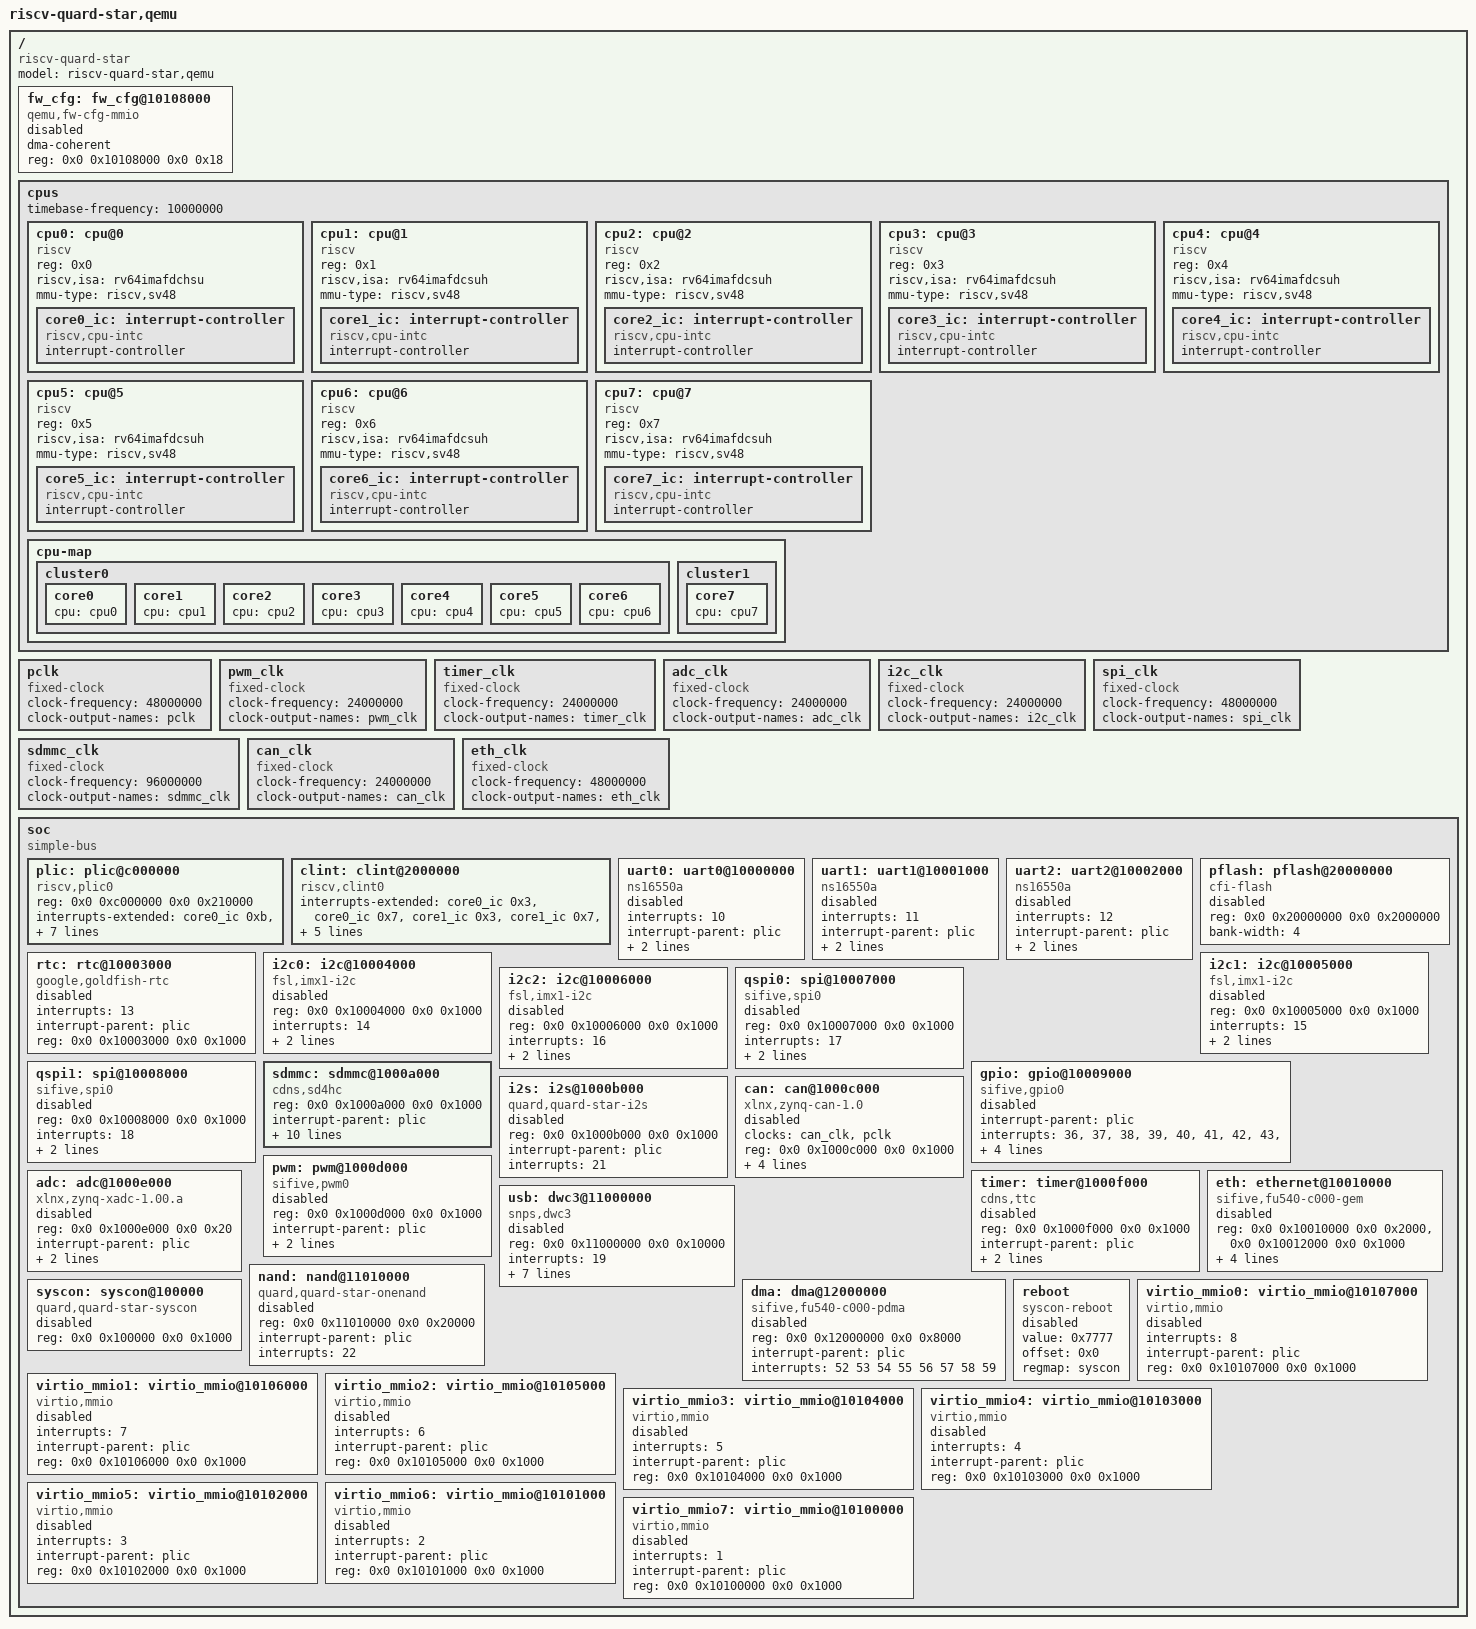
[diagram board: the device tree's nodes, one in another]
/dts-v1/;

/ {
	#address-cells = <0x2>;
	#size-cells = <0x2>;
	compatible = "riscv-quard-star";
	model = "riscv-quard-star,qemu";

	fw_cfg:fw_cfg@10108000 {
		dma-coherent;
		reg = <0x0 0x10108000 0x0 0x18>;
		compatible = "qemu,fw-cfg-mmio";
		status = "disabled";
	};

	cpus {
		#address-cells = <0x1>;
		#size-cells = <0x0>;
		timebase-frequency = <10000000>;

		cpu0: cpu@0 {
			device_type = "cpu";
			reg = <0x0>;
			status = "okay";
			compatible = "riscv";
			riscv,isa = "rv64imafdchsu";
			mmu-type = "riscv,sv48";

			core0_ic:interrupt-controller {
				#interrupt-cells = <0x1>;
				interrupt-controller;
				compatible = "riscv,cpu-intc";
			};
		};

		cpu1: cpu@1 {
			device_type = "cpu";
			reg = <0x1>;
			status = "okay";
			compatible = "riscv";
			riscv,isa = "rv64imafdcsuh";
			mmu-type = "riscv,sv48";

			core1_ic:interrupt-controller {
				#interrupt-cells = <0x1>;
				interrupt-controller;
				compatible = "riscv,cpu-intc";
			};
		};

		cpu2: cpu@2 {
			device_type = "cpu";
			reg = <0x2>;
			status = "okay";
			compatible = "riscv";
			riscv,isa = "rv64imafdcsuh";
			mmu-type = "riscv,sv48";

			core2_ic:interrupt-controller {
				#interrupt-cells = <0x1>;
				interrupt-controller;
				compatible = "riscv,cpu-intc";
			};
		};

		cpu3: cpu@3 {
			device_type = "cpu";
			reg = <0x3>;
			status = "okay";
			compatible = "riscv";
			riscv,isa = "rv64imafdcsuh";
			mmu-type = "riscv,sv48";

			core3_ic:interrupt-controller {
				#interrupt-cells = <0x1>;
				interrupt-controller;
				compatible = "riscv,cpu-intc";
			};
		};

		cpu4: cpu@4 {
			device_type = "cpu";
			reg = <0x4>;
			status = "okay";
			compatible = "riscv";
			riscv,isa = "rv64imafdcsuh";
			mmu-type = "riscv,sv48";

			core4_ic:interrupt-controller {
				#interrupt-cells = <0x1>;
				interrupt-controller;
				compatible = "riscv,cpu-intc";
			};
		};

		cpu5: cpu@5 {
			device_type = "cpu";
			reg = <0x5>;
			status = "okay";
			compatible = "riscv";
			riscv,isa = "rv64imafdcsuh";
			mmu-type = "riscv,sv48";

			core5_ic:interrupt-controller {
				#interrupt-cells = <0x1>;
				interrupt-controller;
				compatible = "riscv,cpu-intc";
			};
		};

		cpu6: cpu@6 {
			device_type = "cpu";
			reg = <0x6>;
			status = "okay";
			compatible = "riscv";
			riscv,isa = "rv64imafdcsuh";
			mmu-type = "riscv,sv48";

			core6_ic:interrupt-controller {
				#interrupt-cells = <0x1>;
				interrupt-controller;
				compatible = "riscv,cpu-intc";
			};
		};

		cpu7: cpu@7 {
			device_type = "cpu";
			reg = <0x7>;
			status = "okay";
			compatible = "riscv";
			riscv,isa = "rv64imafdcsuh";
			mmu-type = "riscv,sv48";

			core7_ic:interrupt-controller {
				#interrupt-cells = <0x1>;
				interrupt-controller;
				compatible = "riscv,cpu-intc";
			};
		};

		cpu-map {

			cluster0 {

				core0 {
					cpu = <&cpu0>;
				};

				core1 {
					cpu = <&cpu1>;
				};

				core2 {
					cpu = <&cpu2>;
				};

				core3 {
					cpu = <&cpu3>;
				};

				core4 {
					cpu = <&cpu4>;
				};

				core5 {
					cpu = <&cpu5>;
				};

				core6 {
					cpu = <&cpu6>;
				};
			};

			cluster1 {
				core7 {
					cpu = <&cpu7>;
				};
			};
		};
	};

	pclk:pclk {
		compatible="fixed-clock";
		clock-frequency=<48000000>;
		clock-output-names="pclk";
		#clock-cells = <0>;
	};

	pwm_clk:pwm_clk {
		compatible="fixed-clock";
		clock-frequency=<24000000>;
		clock-output-names="pwm_clk";
		#clock-cells = <0>;
	};

	timer_clk:timer_clk {
		compatible="fixed-clock";
		clock-frequency=<24000000>;
		clock-output-names="timer_clk";
		#clock-cells = <0>;
	};

	adc_clk:adc_clk {
		compatible="fixed-clock";
		clock-frequency=<24000000>;
		clock-output-names="adc_clk";
		#clock-cells = <0>;
	};

	i2c_clk:i2c_clk {
		compatible="fixed-clock";
		clock-frequency=<24000000>;
		clock-output-names="i2c_clk";
		#clock-cells = <0>;
	};
	
	spi_clk:spi_clk {
		compatible="fixed-clock";
		clock-frequency=<48000000>;
		clock-output-names="spi_clk";
		#clock-cells = <0>;
	};

	sdmmc_clk:sdmmc_clk {
		compatible="fixed-clock";
		clock-frequency=<96000000>;
		clock-output-names="sdmmc_clk";
		#clock-cells = <0>;
	};

	can_clk:can_clk {
		compatible="fixed-clock";
		clock-frequency=<24000000>;
		clock-output-names="can_clk";
		#clock-cells = <0>;
	};

	eth_clk:eth_clk {
		compatible="fixed-clock";
		clock-frequency=<48000000>;
		clock-output-names="eth_clk";
		#clock-cells = <0>;
	};

	soc {
		#address-cells = <0x2>;
		#size-cells = <0x2>;
		compatible = "simple-bus";
		ranges;

		plic:plic@c000000 {
			compatible = "riscv,plic0";
			reg = <0x0 0xc000000 0x0 0x210000>;
			#interrupt-cells = <0x1>;
			#address-cells = <0x0>;
			interrupts-extended = <&core0_ic 0xb &core0_ic 0x9>,
								  <&core1_ic 0xb &core1_ic 0x9>,
								  <&core2_ic 0xb &core2_ic 0x9>,
								  <&core3_ic 0xb &core3_ic 0x9>,
								  <&core4_ic 0xb &core4_ic 0x9>,
								  <&core5_ic 0xb &core5_ic 0x9>,
								  <&core6_ic 0xb &core6_ic 0x9>,
								  <&core7_ic 0xb &core7_ic 0x9>;
			interrupt-controller;
			riscv,ndev = <64>;
		};

		clint:clint@2000000 {
			interrupts-extended = <&core0_ic 0x3 &core0_ic 0x7>,
								  <&core1_ic 0x3 &core1_ic 0x7>,
								  <&core2_ic 0x3 &core2_ic 0x7>,
								  <&core3_ic 0x3 &core3_ic 0x7>,
								  <&core4_ic 0x3 &core4_ic 0x7>,
								  <&core5_ic 0x3 &core5_ic 0x7>,
								  <&core6_ic 0x3 &core6_ic 0x7>,
								  <&core7_ic 0x3 &core7_ic 0x7>;
			reg = <0x0 0x2000000 0x0 0x10000>;
			compatible = "riscv,clint0";
		};

		uart0:uart0@10000000 {
			interrupts = <10>;
			interrupt-parent = <&plic>;
			clock-frequency = <0x384000>;
			reg = <0x0 0x10000000 0x0 0x100>;
			compatible = "ns16550a";
			status = "disabled";
		};

		uart1:uart1@10001000 {
			interrupts = <11>;
			interrupt-parent = <&plic>;
			clock-frequency = <0x384000>;
			reg = <0x0 0x10001000 0x0 0x100>;
			compatible = "ns16550a";
			status = "disabled";
		};

		uart2:uart2@10002000 {
			interrupts = <12>;
			interrupt-parent = <&plic>;
			clock-frequency = <0x384000>;
			reg = <0x0 0x10002000 0x0 0x100>;
			compatible = "ns16550a";
			status = "disabled";
		};
		
		pflash:pflash@20000000 {
			compatible = "cfi-flash";
			reg = <0x0 0x20000000 0x0 0x2000000>;
			bank-width = <4>;
			status = "disabled";
		};
		
		rtc:rtc@10003000 {
			interrupts = <13>;
			interrupt-parent = <&plic>;
			reg = <0x0 0x10003000 0x0 0x1000>;
			compatible = "google,goldfish-rtc";
			status = "disabled";
		};

		i2c0: i2c@10004000 {
			#address-cells = <1>;
			#size-cells = <0>;
			compatible = "fsl,imx1-i2c";
			reg = <0x0 0x10004000 0x0 0x1000>;
			interrupts = <14>;
			interrupt-parent = <&plic>;
			clocks = <&i2c_clk>;
			status = "disabled";
		};
		
		i2c1: i2c@10005000 {
			#address-cells = <1>;
			#size-cells = <0>;
			compatible = "fsl,imx1-i2c";
			reg = <0x0 0x10005000 0x0 0x1000>;
			interrupts = <15>;
			interrupt-parent = <&plic>;
			clocks = <&i2c_clk>;
			status = "disabled";
		};		
		
		i2c2: i2c@10006000 {
			#address-cells = <1>;
			#size-cells = <0>;
			compatible = "fsl,imx1-i2c";
			reg = <0x0 0x10006000 0x0 0x1000>;
			interrupts = <16>;
			interrupt-parent = <&plic>;
			clocks = <&i2c_clk>;
			status = "disabled";
		};

		qspi0: spi@10007000 {
			#address-cells = <1>;
			#size-cells = <0>;
			compatible = "sifive,spi0";
			reg = <0x0 0x10007000 0x0 0x1000>;
			interrupts = <17>;
			interrupt-parent = <&plic>;
			clocks = <&spi_clk>;
			status = "disabled";
		};

		qspi1: spi@10008000 {
			#address-cells = <1>;
			#size-cells = <0>;
			compatible = "sifive,spi0";
			reg = <0x0 0x10008000 0x0 0x1000>;
			interrupts = <18>;
			interrupt-parent = <&plic>;
			clocks = <&spi_clk>;
			status = "disabled";
		};

		gpio: gpio@10009000 {
			compatible = "sifive,gpio0";
			interrupt-parent = <&plic>;
			interrupts = <36>, <37>, <38>, <39>, <40>, <41>, <42>, <43>,
						 <44>, <45>, <46>, <47>, <48>, <49>, <50>, <51>;
			reg = <0x0 0x10009000 0x0 0x1000>;
			gpio-controller;
			#gpio-cells = <2>;
			interrupt-controller;
			#interrupt-cells = <2>;
			status = "disabled";
		};

		sdmmc: sdmmc@1000a000 {
			compatible = "cdns,sd4hc";
			reg = <0x0 0x1000a000 0x0 0x1000>;
			interrupt-parent = <&plic>;
			interrupts = <20>;
			clocks = <&sdmmc_clk>;
			bus-width = <8>;
			mmc-ddr-1_8v;
			mmc-hs200-1_8v;
			cdns,phy-input-delay-legacy = <9>;
			cdns,phy-input-delay-mmc-highspeed = <2>;
			cdns,phy-input-delay-mmc-ddr = <3>;
			cdns,phy-dll-delay-sdclk = <21>;
			cdns,phy-dll-delay-sdclk-hsmmc = <21>;
		};

		i2s: i2s@1000b000 {
			compatible = "quard,quard-star-i2s";
			#sound-dai-cells = <0>;
			reg = <0x0 0x1000b000 0x0 0x1000>;
			interrupt-parent = <&plic>;
			interrupts = <21>;
			status = "disabled";
		};

		can: can@1000c000 {
			compatible = "xlnx,zynq-can-1.0";
			status = "disabled";
			clock-names = "can_clk", "pclk";
			clocks = <&can_clk>, <&pclk>;
			reg = <0x0 0x1000c000 0x0 0x1000>;
			interrupt-parent = <&plic>;
			interrupts = <23>;
			tx-fifo-depth = <0x40>;
			rx-fifo-depth = <0x40>;
		};

		pwm: pwm@1000d000 {
			compatible = "sifive,pwm0";
			reg = <0x0 0x1000d000 0x0 0x1000>;
			interrupt-parent = <&plic>;
			interrupts = <32>, <33>, <34>, <35>;
			clocks = <&pwm_clk>;
			#pwm-cells = <3>;
			status = "disabled";
		};

		adc: adc@1000e000 {
			compatible = "xlnx,zynq-xadc-1.00.a";
			reg = <0x0 0x1000e000 0x0 0x20>;
			interrupt-parent = <&plic>;
			interrupts = <24>;
			clocks = <&adc_clk>;
			status = "disabled";
		};

		timer: timer@1000f000 {
			compatible = "cdns,ttc";
			reg = <0x0 0x1000f000 0x0 0x1000>;
			interrupt-parent = <&plic>;
			interrupts = <29>, <30>, <31>;
			clocks = <&timer_clk>;
			status = "disabled";
		};

		eth: ethernet@10010000 {
			compatible = "sifive,fu540-c000-gem";
			reg = <0x0 0x10010000 0x0 0x2000>,
			      <0x0 0x10012000 0x0 0x1000>;
			interrupt-parent = <&plic>;
			interrupts = <25>;
			local-mac-address = [52 54 00 12 34 55];
			clock-names = "pclk", "hclk";
			clocks = <&eth_clk>, <&eth_clk>;
			#address-cells = <1>;
			#size-cells = <0>;
			status = "disabled";
		};

		usb: dwc3@11000000 {
			compatible = "snps,dwc3";
			reg = <0x0 0x11000000 0x0 0x10000>;
			interrupts = <19>;
			interrupt-parent = <&plic>;
			status = "disabled";
			phy-names = "usb3-phy";
			dr_mode = "host";
			snps,quirk-frame-length-adjustment = <0x20>;
			snps,dis_u2_susphy_quirk;
			snps,dis_u3_susphy_quirk;
			snps,refclk_fladj;
			snps,mask_phy_reset;
		};

		nand: nand@11010000 {
			compatible = "quard,quard-star-onenand";
			reg = <0x0 0x11010000 0x0 0x20000>;
			interrupt-parent = <&plic>;
			interrupts = <22>;
			status = "disabled";
		};

		dma: dma@12000000 {
			compatible = "sifive,fu540-c000-pdma";
			reg = <0x0 0x12000000 0x0 0x8000>;
			interrupt-parent = <&plic>;
			interrupts = <52 53 54 55 56 57 58 59>;
			#dma-cells = <1>;
			status = "disabled";
		};

		syscon:syscon@100000 {
			reg = <0x0 0x100000 0x0 0x1000>;
			compatible = "quard,quard-star-syscon","sifive,test1", "sifive,test0", "syscon";
			status = "disabled";
		};

		reboot:reboot {
			value = <0x7777>;
			offset = <0x0>;
			regmap = <&syscon>;
			compatible = "syscon-reboot";
			status = "disabled";
		};
	
		virtio_mmio0:virtio_mmio@10107000 {
			interrupts = <8>;
			interrupt-parent = <&plic>;
			reg = <0x0 0x10107000 0x0 0x1000>;
			compatible = "virtio,mmio";
			status = "disabled";
		};

		virtio_mmio1:virtio_mmio@10106000 {
			interrupts = <7>;
			interrupt-parent = <&plic>;
			reg = <0x0 0x10106000 0x0 0x1000>;
			compatible = "virtio,mmio";
			status = "disabled";
		};

		virtio_mmio2:virtio_mmio@10105000 {
			interrupts = <6>;
			interrupt-parent = <&plic>;
			reg = <0x0 0x10105000 0x0 0x1000>;
			compatible = "virtio,mmio";
			status = "disabled";
		};

		virtio_mmio3:virtio_mmio@10104000 {
			interrupts = <5>;
			interrupt-parent = <&plic>;
			reg = <0x0 0x10104000 0x0 0x1000>;
			compatible = "virtio,mmio";
			status = "disabled";
		};

		virtio_mmio4:virtio_mmio@10103000 {
			interrupts = <4>;
			interrupt-parent = <&plic>;
			reg = <0x0 0x10103000 0x0 0x1000>;
			compatible = "virtio,mmio";
			status = "disabled";
		};

		virtio_mmio5:virtio_mmio@10102000 {
			interrupts = <3>;
			interrupt-parent = <&plic>;
			reg = <0x0 0x10102000 0x0 0x1000>;
			compatible = "virtio,mmio";
			status = "disabled";
		};

		virtio_mmio6:virtio_mmio@10101000 {
			interrupts = <2>;
			interrupt-parent = <&plic>;
			reg = <0x0 0x10101000 0x0 0x1000>;
			compatible = "virtio,mmio";
			status = "disabled";
		};

		virtio_mmio7:virtio_mmio@10100000 {
			interrupts = <1>;
			interrupt-parent = <&plic>;
			reg = <0x0 0x10100000 0x0 0x1000>;
			compatible = "virtio,mmio";
			status = "disabled";
		};
	};
};
